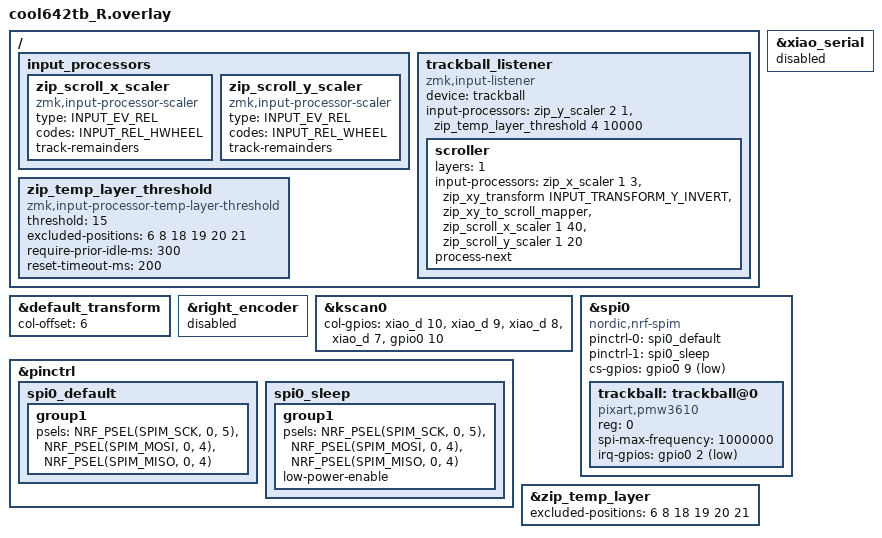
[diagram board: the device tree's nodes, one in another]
#include "cool642tb.dtsi"

&default_transform {
    col-offset = <6>;
};

&right_encoder {
  status = "disabled";
};

&kscan0 {
        col-gpios
            = <&xiao_d 10 GPIO_ACTIVE_HIGH>
            , <&xiao_d 9 GPIO_ACTIVE_HIGH> 
            , <&xiao_d 8 GPIO_ACTIVE_HIGH> 
            , <&xiao_d 7 GPIO_ACTIVE_HIGH> 
            , <&gpio0 10 GPIO_ACTIVE_HIGH>
            ;
};

&pinctrl {
    spi0_default: spi0_default {
        group1 {
            psels = <NRF_PSEL(SPIM_SCK,  0, 5)>,
                    <NRF_PSEL(SPIM_MOSI, 0, 4)>,
                    <NRF_PSEL(SPIM_MISO, 0, 4)>;
        };
    };

    spi0_sleep: spi0_sleep {
        group1 {
            psels = <NRF_PSEL(SPIM_SCK,  0, 5)>,
                    <NRF_PSEL(SPIM_MOSI, 0, 4)>,
                    <NRF_PSEL(SPIM_MISO, 0, 4)>;
            low-power-enable;
        };
    };
};

&xiao_serial { status = "disabled"; };

&spi0 {
    status = "okay";
    compatible = "nordic,nrf-spim";
    pinctrl-0 = <&spi0_default>;
    pinctrl-1 = <&spi0_sleep>;
    pinctrl-names = "default", "sleep";
    cs-gpios = <&gpio0 9 GPIO_ACTIVE_LOW>;

    trackball: trackball@0 {
        status = "okay";
        compatible = "pixart,pmw3610";
        reg = <0>;
        spi-max-frequency = <1000000>;
        irq-gpios = <&gpio0 2 (GPIO_ACTIVE_LOW | GPIO_PULL_UP)>;

    };
};

#include <input/processors.dtsi>
#include <dt-bindings/zmk/input_transform.h>
#include <zephyr/dt-bindings/input/input-event-codes.h>
&zip_temp_layer {
    excluded-positions = <
        6  // U
        8  // O
        18 // J
        19 // K　　　　
        20 // L
        21
    >;
};

/ {
    input_processors {
        zip_scroll_x_scaler: zip_scroll_x_scaler {
            compatible = "zmk,input-processor-scaler";
            #input-processor-cells = <2>;
            type = <INPUT_EV_REL>;
            codes = <INPUT_REL_HWHEEL>;
            track-remainders;
        };

        zip_scroll_y_scaler: zip_scroll_y_scaler {
            compatible = "zmk,input-processor-scaler";
            #input-processor-cells = <2>;
            type = <INPUT_EV_REL>;
            codes = <INPUT_REL_WHEEL>;
            track-remainders;
        };
    };
};

/ {
    trackball_listener: trackball_listener {
        compatible = "zmk,input-listener";
        device = <&trackball>;
        scroller {
        layers = <1>;
        
        input-processors = <
            &zip_x_scaler 1 3    // X方向を1/3に抑制
            &zip_xy_transform INPUT_TRANSFORM_Y_INVERT
            &zip_xy_to_scroll_mapper  
            &zip_scroll_x_scaler 1 40
            &zip_scroll_y_scaler 1 20
                               
        >;
        process-next; 
    };
        input-processors = <
            &zip_y_scaler 2 1
            &zip_temp_layer_threshold 4 10000
        >;

    };
};

/ {
    zip_temp_layer_threshold: zip_temp_layer_threshold {
        compatible = "zmk,input-processor-temp-layer-threshold";
        #input-processor-cells = <2>;

        threshold = <15>;              // まずは 10〜20 くらいで調整
        excluded-positions = <6 8 18 19 20 21>;   // ここは「クリックに使うキー」を入れる（J/L）
        require-prior-idle-ms = <300>;  // タイピング直後はAMLに入らない（超重要）
        reset-timeout-ms = <200>;       // ちょい止めたら累積移動をリセット
    };
};
